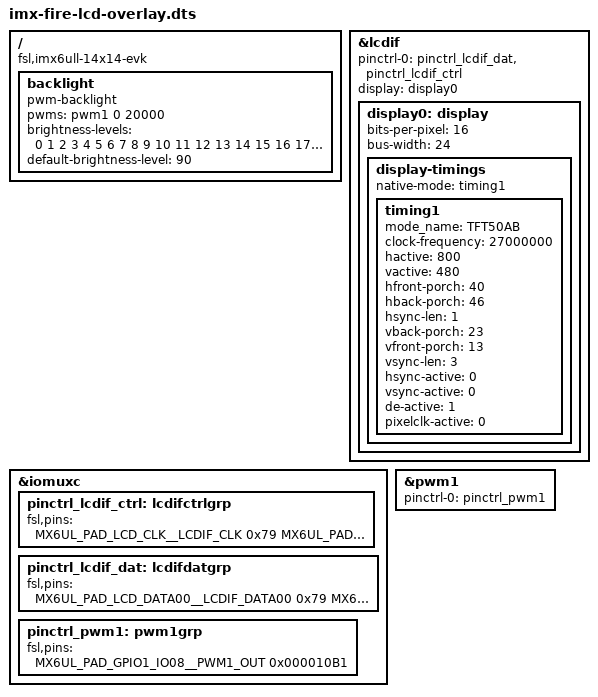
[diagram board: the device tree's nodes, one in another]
/*
 * Copyright (C) 2019 - All Rights Reserved by 
 * filename : imx-fire-lcd5-overlay.dts
 * brief : Device Tree overlay for EBF6ull lcd5' or lcd7' device
 * author : embedfire
 * date : 2019-11-19 
 * version : A001
 */
#include "../imx6ull-pinfunc.h"
#include "../imx6ull-pinfunc-snvs.h"
#include "dt-bindings/interrupt-controller/irq.h"
#include "dt-bindings/gpio/gpio.h"
/dts-v1/;
/plugin/;

/ {
     compatible = "fsl,imx6ull-14x14-evk", "fsl,imx6ull";

        fragment@0 {
                target = <&lcdif>;
                __overlay__ {
                    pinctrl-names = "default";
                    pinctrl-0 = <&pinctrl_lcdif_dat &pinctrl_lcdif_ctrl>;
                    display = <&display0>;
                    status = "okay";

                	display0: display {
                		bits-per-pixel = <16>;
                		bus-width = <24>;

                		display-timings {
                			native-mode = <&timing1>;

                		timing1: timing1 {
		                        mode_name = "TFT50AB";
		                        clock-frequency = <27000000>;
		                        hactive = <800>;
		                        vactive = <480>;
		                        hfront-porch = <40>;
		                        hback-porch = <46>;
		                        hsync-len = <1>;
		                        vback-porch = <23>;
		                        vfront-porch = <13>;
		                        vsync-len = <3>;

                                 /*
                                    旧的5寸屏 / 7寸屏通用时序：
                                    .hbp = 46,   //HSYNC后的无效像素
                                    .vbp = 23,  //VSYNC后的无效行数

                                    .hsw = 1,   //HSYNC宽度
                                    .vsw = 1,   //VSYNC宽度

                                    .hfp = 22,          //HSYNC前的无效像素
                                    .vfp = 22,          //VSYNC前的无效行数


                                    厂家给的新5寸屏的时序：（该时序不兼容7寸屏，并且有些问题）
                                    .hbp = 0,   //HSYNC后的无效像素
                                    .vbp = 45,  //VSYNC后的无效行数

                                    .hsw = 128,   //HSYNC宽度
                                    .vsw = 128,   //VSYNC宽度

                                    .hfp = 88,          //HSYNC前的无效像素
                                    .vfp = 13,          //VSYNC前的无效行数


                                    调整过后的最终时序：（能兼容新旧5寸屏和7寸屏）
                                    .hbp = 46,  //HSYNC后的无效像素
                                    .vbp = 23,  //VSYNC后的无效行数

                                    .hsw = 1,   //HSYNC宽度
                                    .vsw = 3,   //VSYNC宽度

                                    .hfp = 40,  //HSYNC前的无效像素
                                    .vfp = 13,  //VSYNC前的无效行数
                                 */

		                        hsync-active = <0>;
		                        vsync-active = <0>;
		                        de-active = <1>;
		                        pixelclk-active = <0>;
                			};
                		};
                	};
                };
            };
        fragment@1 {
                target = <&iomuxc>;
                __overlay__ {
                    pinctrl_lcdif_ctrl: lcdifctrlgrp {
                        fsl,pins = <
                            MX6UL_PAD_LCD_CLK__LCDIF_CLK	    0x79
                            MX6UL_PAD_LCD_ENABLE__LCDIF_ENABLE  0x79
                            MX6UL_PAD_LCD_HSYNC__LCDIF_HSYNC    0x79
                            MX6UL_PAD_LCD_VSYNC__LCDIF_VSYNC    0x79
                        >;
                    };
                    pinctrl_lcdif_dat: lcdifdatgrp {
                        fsl,pins = <
                            MX6UL_PAD_LCD_DATA00__LCDIF_DATA00  0x79
                            MX6UL_PAD_LCD_DATA01__LCDIF_DATA01  0x79
                            MX6UL_PAD_LCD_DATA02__LCDIF_DATA02  0x79
                            MX6UL_PAD_LCD_DATA03__LCDIF_DATA03  0x79
                            MX6UL_PAD_LCD_DATA04__LCDIF_DATA04  0x79
                            MX6UL_PAD_LCD_DATA05__LCDIF_DATA05  0x79
                            MX6UL_PAD_LCD_DATA06__LCDIF_DATA06  0x79
                            MX6UL_PAD_LCD_DATA07__LCDIF_DATA07  0x79
                            MX6UL_PAD_LCD_DATA08__LCDIF_DATA08  0x79
                            MX6UL_PAD_LCD_DATA09__LCDIF_DATA09  0x79
                            MX6UL_PAD_LCD_DATA10__LCDIF_DATA10  0x79
                            MX6UL_PAD_LCD_DATA11__LCDIF_DATA11  0x79
                            MX6UL_PAD_LCD_DATA12__LCDIF_DATA12  0x79
                            MX6UL_PAD_LCD_DATA13__LCDIF_DATA13  0x79
                            MX6UL_PAD_LCD_DATA14__LCDIF_DATA14  0x79
                            MX6UL_PAD_LCD_DATA15__LCDIF_DATA15  0x79
                            MX6UL_PAD_LCD_DATA16__LCDIF_DATA16  0x79
                            MX6UL_PAD_LCD_DATA17__LCDIF_DATA17  0x79
                            MX6UL_PAD_LCD_DATA18__LCDIF_DATA18  0x79
                            MX6UL_PAD_LCD_DATA19__LCDIF_DATA19  0x79
                            MX6UL_PAD_LCD_DATA20__LCDIF_DATA20  0x79
                            MX6UL_PAD_LCD_DATA21__LCDIF_DATA21  0x79
                            MX6UL_PAD_LCD_DATA22__LCDIF_DATA22  0x79
                            MX6UL_PAD_LCD_DATA23__LCDIF_DATA23  0x79
                        >;
                    };
                    pinctrl_pwm1: pwm1grp {
                        fsl,pins = <
                            MX6UL_PAD_GPIO1_IO08__PWM1_OUT   0x000010B1
                        >;
                    };
                };
        };
	fragment@2 {
		target-path = "/";
		__overlay__ {
			backlight {
				compatible = "pwm-backlight";
				//pwms = <&pwm1 0 50000>;
                pwms = <&pwm1 0 20000>;
				brightness-levels = <0 1 2 3 4 5 6 7 8 9 10 11 12 13 14 15 16 17 18 19 20 21 22 23 24 25 26 27 28 29 30 31 32 33 34 35 36 37 38 39 40 41 42 43 44 45 46 47 48 49 50 51 52 53 54 55 56 57 58 59 60 61 62 63 64 65 66 67 68 69 70 71 72 73 74 75 76 77 78 79 80 81 82 83 84 85 86 87 88 89 90 91 92 93 94 95 96 97 98 99 100>;
				default-brightness-level = <90>;
				status = "okay";
			};			
		};	
	};	
	fragment@3 {
		target=<&pwm1>;
		__overlay__ {
			pinctrl-names = "default";
			pinctrl-0 = <&pinctrl_pwm1>;
			status = "okay";
		};
	
	};
};

/{
	__overrides__ {
		clock-frequency_0 = <&timing1>,"clock-frequency:0";
		hactive_0 = <&timing1>,"hactive:0";
		vactive_0 = <&timing1>,"vactive:0";
		hfront-porch_0 = <&timing1>,"hfront-porch:0";
		hback-porch_0 = <&timing1>,"hback-porch:0";
		hsync-len_0 = <&timing1>,"hsync-len:0";
		vback-porch_0 = <&timing1>,"vback-porch:0";
		vfront-porch_0 = <&timing1>,"vfront-porch:0";	
		vsync-len_0 = <&timing1>,"vsync-len:0";	
		bits-per-pixel_0 = <&display0>,"bits-per-pixel:0";
	};

};
